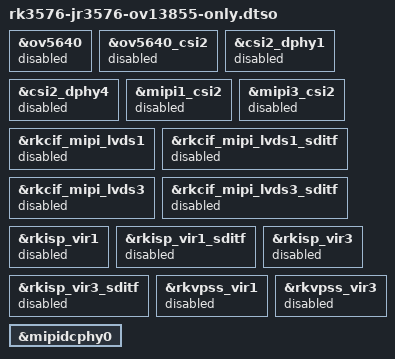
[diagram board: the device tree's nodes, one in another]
// SPDX-License-Identifier: (GPL-2.0+ OR MIT)
/dts-v1/;
/plugin/;

/* JR3576 CSI1 OV13855 is supplied by the base DTB. Disable the two
 * unattached OV5640 pipelines so RKAIQ does not initialize fake cameras. */
&ov5640 { status = "disabled"; };
&ov5640_csi2 { status = "disabled"; };
&csi2_dphy1 { status = "disabled"; };
&csi2_dphy4 { status = "disabled"; };
&mipi1_csi2 { status = "disabled"; };
&mipi3_csi2 { status = "disabled"; };
&rkcif_mipi_lvds1 { status = "disabled"; };
&rkcif_mipi_lvds1_sditf { status = "disabled"; };
&rkcif_mipi_lvds3 { status = "disabled"; };
&rkcif_mipi_lvds3_sditf { status = "disabled"; };
&rkisp_vir1 { status = "disabled"; };
&rkisp_vir1_sditf { status = "disabled"; };
&rkisp_vir3 { status = "disabled"; };
&rkisp_vir3_sditf { status = "disabled"; };
&rkvpss_vir1 { status = "disabled"; };
&rkvpss_vir3 { status = "disabled"; };
&mipidcphy0 { status = "okay"; };
